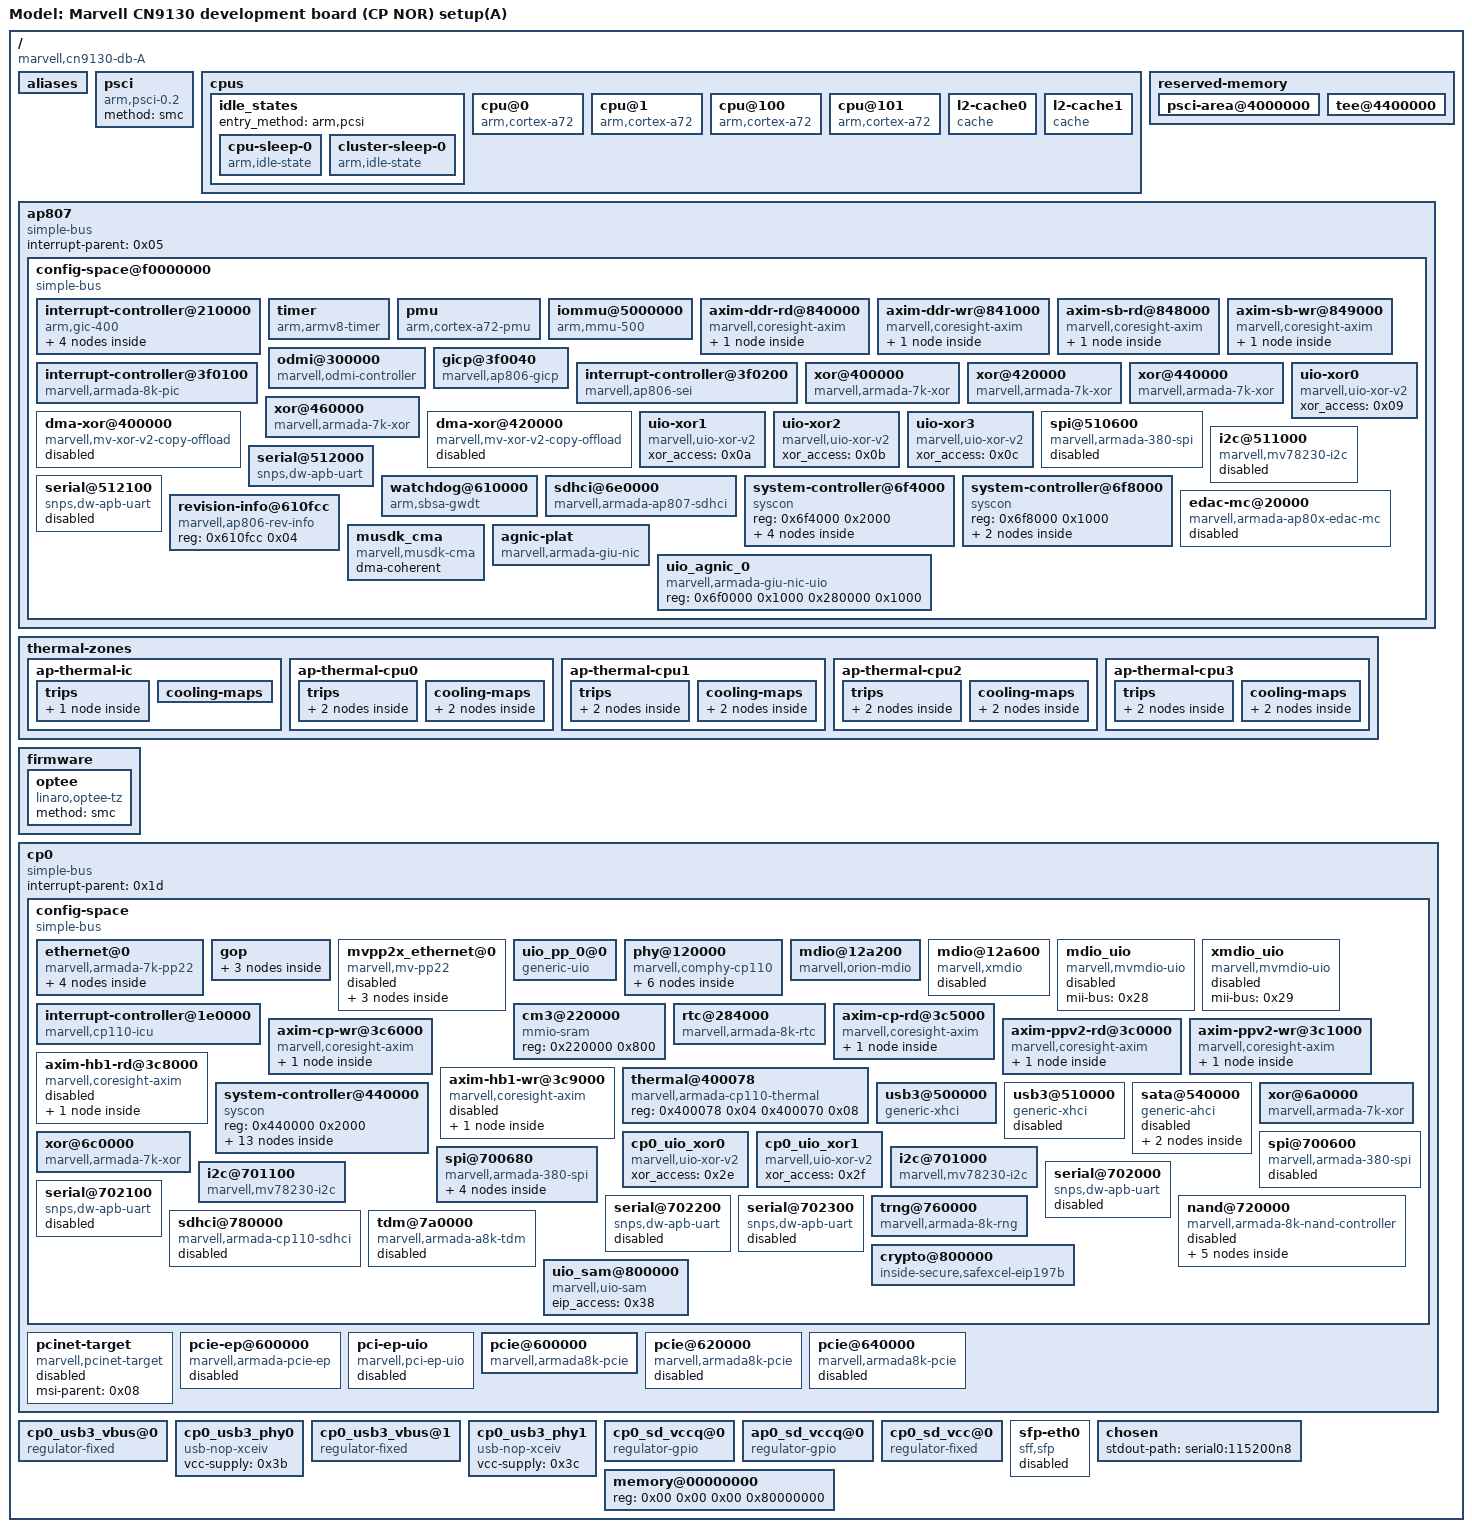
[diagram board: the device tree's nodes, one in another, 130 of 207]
/dts-v1/;

/ {
	compatible = "marvell,cn9130-db-A\0marvell,armada-ap807-quad\0marvell,armada-ap807";
	#address-cells = <0x02>;
	#size-cells = <0x02>;
	model = "Model: Marvell CN9130 development board (CP NOR) setup(A)";

	aliases {
		serial0 = "/ap807/config-space@f0000000/serial@512000";
		serial1 = "/ap807/config-space@f0000000/serial@512100";
		gpio0 = "/ap807/config-space@f0000000/system-controller@6f4000/gpio@1040";
		spi0 = "/ap807/config-space@f0000000/spi@510600";
		gpio1 = "/cp0/config-space/system-controller@440000/gpio@100";
		gpio2 = "/cp0/config-space/system-controller@440000/gpio@140";
		spi1 = "/cp0/config-space/spi@700600";
		spi2 = "/cp0/config-space/spi@700680";
		i2c0 = "/cp0/config-space/i2c@701000";
		ethernet0 = "/cp0/config-space/ethernet@0/eth0";
		ethernet1 = "/cp0/config-space/ethernet@0/eth1";
		ethernet2 = "/cp0/config-space/ethernet@0/eth2";
	};

	psci {
		compatible = "arm,psci-0.2";
		method = "smc";
	};

	cpus {
		#address-cells = <0x01>;
		#size-cells = <0x00>;

		idle_states {
			entry_method = "arm,pcsi";

			cpu-sleep-0 {
				compatible = "arm,idle-state";
				local-timer-stop;
				arm,psci-suspend-param = <0x10000>;
				entry-latency-us = <0x50>;
				exit-latency-us = <0xa0>;
				min-residency-us = <0x140>;
				linux,phandle = <0x02>;
				phandle = <0x02>;
			};

			cluster-sleep-0 {
				compatible = "arm,idle-state";
				local-timer-stop;
				arm,psci-suspend-param = <0x1010000>;
				entry-latency-us = <0x1f4>;
				exit-latency-us = <0x3e8>;
				min-residency-us = <0x9c4>;
			};
		};

		cpu@0 {
			device_type = "cpu";
			compatible = "arm,cortex-a72\0arm,armv8";
			reg = <0x00>;
			enable-method = "psci";
			#cooling-cells = <0x02>;
			clocks = <0x01 0x00>;
			cpu-idle-states = <0x02>;
			i-cache-size = <0xc000>;
			i-cache-line-size = <0x40>;
			i-cache-sets = <0x100>;
			d-cache-size = <0x8000>;
			d-cache-line-size = <0x40>;
			d-cache-sets = <0x100>;
			next-level-cache = <0x03>;
			linux,phandle = <0x12>;
			phandle = <0x12>;
		};

		cpu@1 {
			device_type = "cpu";
			compatible = "arm,cortex-a72\0arm,armv8";
			reg = <0x01>;
			enable-method = "psci";
			#cooling-cells = <0x02>;
			clocks = <0x01 0x00>;
			cpu-idle-states = <0x02>;
			i-cache-size = <0xc000>;
			i-cache-line-size = <0x40>;
			i-cache-sets = <0x100>;
			d-cache-size = <0x8000>;
			d-cache-line-size = <0x40>;
			d-cache-sets = <0x100>;
			next-level-cache = <0x03>;
			linux,phandle = <0x13>;
			phandle = <0x13>;
		};

		cpu@100 {
			device_type = "cpu";
			compatible = "arm,cortex-a72\0arm,armv8";
			reg = <0x100>;
			enable-method = "psci";
			#cooling-cells = <0x02>;
			clocks = <0x01 0x01>;
			cpu-idle-states = <0x02>;
			i-cache-size = <0xc000>;
			i-cache-line-size = <0x40>;
			i-cache-sets = <0x100>;
			d-cache-size = <0x8000>;
			d-cache-line-size = <0x40>;
			d-cache-sets = <0x100>;
			next-level-cache = <0x04>;
			linux,phandle = <0x18>;
			phandle = <0x18>;
		};

		cpu@101 {
			device_type = "cpu";
			compatible = "arm,cortex-a72\0arm,armv8";
			reg = <0x101>;
			enable-method = "psci";
			#cooling-cells = <0x02>;
			clocks = <0x01 0x01>;
			cpu-idle-states = <0x02>;
			i-cache-size = <0xc000>;
			i-cache-line-size = <0x40>;
			i-cache-sets = <0x100>;
			d-cache-size = <0x8000>;
			d-cache-line-size = <0x40>;
			d-cache-sets = <0x100>;
			next-level-cache = <0x04>;
			linux,phandle = <0x19>;
			phandle = <0x19>;
		};

		l2-cache0 {
			compatible = "cache";
			cache-size = <0x80000>;
			cache-line-size = <0x40>;
			cache-sets = <0x200>;
			linux,phandle = <0x03>;
			phandle = <0x03>;
		};

		l2-cache1 {
			compatible = "cache";
			cache-size = <0x80000>;
			cache-line-size = <0x40>;
			cache-sets = <0x200>;
			linux,phandle = <0x04>;
			phandle = <0x04>;
		};
	};

	reserved-memory {
		#address-cells = <0x02>;
		#size-cells = <0x02>;
		ranges;

		psci-area@4000000 {
			reg = <0x00 0x4000000 0x00 0x200000>;
			no-map;
		};

		tee@4400000 {
			reg = <0x00 0x4400000 0x00 0x1000000>;
			no-map;
		};
	};

	ap807 {
		#address-cells = <0x02>;
		#size-cells = <0x02>;
		compatible = "simple-bus";
		interrupt-parent = <0x05>;
		ranges;

		config-space@f0000000 {
			#address-cells = <0x01>;
			#size-cells = <0x01>;
			compatible = "simple-bus";
			ranges = <0x00 0x00 0xf0000000 0x1000000>;

			interrupt-controller@210000 {
				compatible = "arm,gic-400";
				#interrupt-cells = <0x03>;
				#address-cells = <0x01>;
				#size-cells = <0x01>;
				ranges;
				interrupt-controller;
				interrupts = <0x01 0x09 0xf04>;
				reg = <0x210000 0x10000 0x220000 0x20000 0x240000 0x20000 0x260000 0x20000>;
				linux,phandle = <0x05>;
				phandle = <0x05>;

				v2m@280000 {
					compatible = "arm,gic-v2m-frame";
					msi-controller;
					reg = <0x280000 0x1000>;
					arm,msi-base-spi = <0xa0>;
					arm,msi-num-spis = <0x20>;
					linux,phandle = <0x08>;
					phandle = <0x08>;
				};

				v2m@290000 {
					compatible = "arm,gic-v2m-frame";
					msi-controller;
					reg = <0x290000 0x1000>;
					arm,msi-base-spi = <0xc0>;
					arm,msi-num-spis = <0x20>;
				};

				v2m@2a0000 {
					compatible = "arm,gic-v2m-frame";
					msi-controller;
					reg = <0x2a0000 0x1000>;
					arm,msi-base-spi = <0xe0>;
					arm,msi-num-spis = <0x20>;
				};

				v2m@2b0000 {
					compatible = "arm,gic-v2m-frame";
					msi-controller;
					reg = <0x2b0000 0x1000>;
					arm,msi-base-spi = <0x100>;
					arm,msi-num-spis = <0x20>;
				};
			};

			timer {
				compatible = "arm,armv8-timer";
				interrupts = <0x01 0x0d 0xf08 0x01 0x0e 0xf08 0x01 0x0b 0xf08 0x01 0x0a 0xf08>;
			};

			pmu {
				compatible = "arm,cortex-a72-pmu";
				interrupt-parent = <0x06>;
				interrupts = <0x11>;
			};

			iommu@5000000 {
				compatible = "arm,mmu-500";
				reg = <0x100000 0x100000>;
				dma-coherent;
				#iommu-cells = <0x01>;
				#global-interrupts = <0x01>;
				interrupts = <0x00 0x06 0x04 0x00 0x06 0x04 0x00 0x06 0x04 0x00 0x06 0x04 0x00 0x06 0x04 0x00 0x06 0x04 0x00 0x06 0x04 0x00 0x06 0x04 0x00 0x06 0x04>;
			};

			axim-ddr-rd@840000 {
				compatible = "marvell,coresight-axim\0arm,primecell";
				reg = <0x840000 0x1000>;
				clocks = <0x07 0x03 0x07 0x05>;
				clock-names = "apb_pclk\0hclk";
				bus-width = <0x28>;

				port@0 {
				};
			};

			axim-ddr-wr@841000 {
				compatible = "marvell,coresight-axim\0arm,primecell";
				reg = <0x841000 0x1000>;
				clocks = <0x07 0x03 0x07 0x05>;
				clock-names = "apb_pclk\0hclk";
				bus-width = <0x28>;

				port@0 {
				};
			};

			axim-sb-rd@848000 {
				compatible = "marvell,coresight-axim\0arm,primecell";
				reg = <0x848000 0x1000>;
				clocks = <0x07 0x03 0x07 0x05>;
				clock-names = "apb_pclk\0hclk";
				bus-width = <0x28>;

				port@0 {
				};
			};

			axim-sb-wr@849000 {
				compatible = "marvell,coresight-axim\0arm,primecell";
				reg = <0x849000 0x1000>;
				clocks = <0x07 0x03 0x07 0x05>;
				clock-names = "apb_pclk\0hclk";
				bus-width = <0x28>;

				port@0 {
				};
			};

			odmi@300000 {
				compatible = "marvell,odmi-controller";
				interrupt-controller;
				msi-controller;
				marvell,odmi-frames = <0x04>;
				reg = <0x300000 0x4000 0x304000 0x4000 0x308000 0x4000 0x30c000 0x4000>;
				marvell,spi-base = <0x80 0x88 0x90 0x98>;
			};

			gicp@3f0040 {
				compatible = "marvell,ap806-gicp";
				reg = <0x3f0040 0x10>;
				marvell,spi-ranges = <0x40 0x40 0x120 0x40>;
				msi-controller;
				linux,phandle = <0x2a>;
				phandle = <0x2a>;
			};

			interrupt-controller@3f0100 {
				compatible = "marvell,armada-8k-pic";
				reg = <0x3f0100 0x10>;
				#interrupt-cells = <0x01>;
				interrupt-controller;
				interrupts = <0x01 0x0f 0x04>;
				linux,phandle = <0x06>;
				phandle = <0x06>;
			};

			interrupt-controller@3f0200 {
				compatible = "marvell,ap806-sei";
				reg = <0x3f0200 0x40>;
				interrupts = <0x00 0x00 0x04>;
				#interrupt-cells = <0x01>;
				interrupt-controller;
				msi-controller;
				linux,phandle = <0x0f>;
				phandle = <0x0f>;
			};

			xor@400000 {
				compatible = "marvell,armada-7k-xor\0marvell,xor-v2";
				reg = <0x400000 0x1000 0x410000 0x1000>;
				msi-parent = <0x08>;
				clocks = <0x07 0x03>;
				dma-coherent;
				linux,phandle = <0x09>;
				phandle = <0x09>;
			};

			xor@420000 {
				compatible = "marvell,armada-7k-xor\0marvell,xor-v2";
				reg = <0x420000 0x1000 0x430000 0x1000>;
				msi-parent = <0x08>;
				clocks = <0x07 0x03>;
				dma-coherent;
				linux,phandle = <0x0a>;
				phandle = <0x0a>;
			};

			xor@440000 {
				compatible = "marvell,armada-7k-xor\0marvell,xor-v2";
				reg = <0x440000 0x1000 0x450000 0x1000>;
				msi-parent = <0x08>;
				clocks = <0x07 0x03>;
				dma-coherent;
				linux,phandle = <0x0b>;
				phandle = <0x0b>;
			};

			xor@460000 {
				compatible = "marvell,armada-7k-xor\0marvell,xor-v2";
				reg = <0x460000 0x1000 0x470000 0x1000>;
				msi-parent = <0x08>;
				clocks = <0x07 0x03>;
				dma-coherent;
				linux,phandle = <0x0c>;
				phandle = <0x0c>;
			};

			dma-xor@400000 {
				compatible = "marvell,mv-xor-v2-copy-offload";
				reg = <0x400000 0x1000 0x410000 0x1000>;
				msi-parent = <0x08>;
				clocks = <0x07 0x03>;
				dma-coherent;
				status = "disabled";
			};

			dma-xor@420000 {
				compatible = "marvell,mv-xor-v2-copy-offload";
				reg = <0x420000 0x1000 0x430000 0x1000>;
				msi-parent = <0x08>;
				clocks = <0x07 0x03>;
				dma-coherent;
				status = "disabled";
			};

			uio-xor0 {
				compatible = "marvell,uio-xor-v2";
				xor_access = <0x09>;
			};

			uio-xor1 {
				compatible = "marvell,uio-xor-v2";
				xor_access = <0x0a>;
			};

			uio-xor2 {
				compatible = "marvell,uio-xor-v2";
				xor_access = <0x0b>;
			};

			uio-xor3 {
				compatible = "marvell,uio-xor-v2";
				xor_access = <0x0c>;
			};

			spi@510600 {
				compatible = "marvell,armada-380-spi";
				reg = <0x510600 0x50>;
				#address-cells = <0x01>;
				#size-cells = <0x00>;
				interrupts = <0x00 0x15 0x04>;
				clocks = <0x07 0x03>;
				status = "disabled";
			};

			i2c@511000 {
				compatible = "marvell,mv78230-i2c";
				reg = <0x511000 0x20>;
				#address-cells = <0x01>;
				#size-cells = <0x00>;
				interrupts = <0x00 0x14 0x04>;
				timeout-ms = <0x3e8>;
				clocks = <0x07 0x03>;
				status = "disabled";
			};

			serial@512000 {
				compatible = "snps,dw-apb-uart";
				reg = <0x512000 0x100>;
				reg-shift = <0x02>;
				interrupts = <0x00 0x13 0x04>;
				reg-io-width = <0x01>;
				clocks = <0x07 0x03>;
				status = "okay";
			};

			serial@512100 {
				compatible = "snps,dw-apb-uart";
				reg = <0x512100 0x100>;
				reg-shift = <0x02>;
				interrupts = <0x00 0x1d 0x04>;
				reg-io-width = <0x01>;
				clocks = <0x07 0x03>;
				status = "disabled";
			};

			watchdog@610000 {
				compatible = "arm,sbsa-gwdt";
				reg = <0x610000 0x1000 0x600000 0x1000>;
				interrupts = <0x00 0x02 0x04>;
			};

			sdhci@6e0000 {
				compatible = "marvell,armada-ap807-sdhci";
				reg = <0x6e0000 0x300>;
				interrupts = <0x00 0x10 0x04>;
				clock-names = "core";
				clocks = <0x07 0x04>;
				dma-coherent;
				status = "okay";
				pinctrl-names = "default";
				max-frequency = <0x18cba80>;
				bus-width = <0x08>;
				no-1-8-v;
				mmc-ddr-3_3v;
				disable-wp;
				broken-cd;
				cap-mmc-highspeed;
				non-removable;
				no-sdio;
				no-sd;
				vqmmc-supply = <0x325aa0>;
			};

			system-controller@6f4000 {
				compatible = "syscon\0simple-mfd";
				reg = <0x6f4000 0x2000>;

				pinctrl {
					compatible = "marvell,ap806-pinctrl";
					linux,phandle = <0x0e>;
					phandle = <0x0e>;

					uart0-pins {
						marvell,pins = "mpp11\0mpp19";
						marvell,function = "uart0";
					};
				};

				gpio@1040 {
					compatible = "marvell,armada-8k-gpio";
					offset = <0x1040>;
					ngpios = <0x14>;
					gpio-controller;
					#gpio-cells = <0x02>;
					gpio-ranges = <0x0e 0x00 0x00 0x14>;
				};

				clock {
					compatible = "marvell,ap807-clock";
					#clock-cells = <0x01>;
					linux,phandle = <0x07>;
					phandle = <0x07>;
				};
			};

			system-controller@6f8000 {
				compatible = "syscon\0simple-mfd";
				reg = <0x6f8000 0x1000>;
				#address-cells = <0x01>;
				#size-cells = <0x01>;

				thermal-sensor@80 {
					compatible = "marvell,armada-ap806-thermal";
					reg = <0x80 0x10>;
					interrupt-parent = <0x0f>;
					interrupts = <0x12>;
					#thermal-sensor-cells = <0x01>;
					linux,phandle = <0x10>;
					phandle = <0x10>;
				};

				clock-cpu {
					compatible = "marvell,ap807-cpu-clock";
					clocks = <0x07 0x00 0x07 0x01>;
					#clock-cells = <0x01>;
					linux,phandle = <0x01>;
					phandle = <0x01>;
				};
			};

			edac-mc@20000 {
				compatible = "marvell,armada-ap80x-edac-mc";
				reg = <0x20000 0x1000>;
				interrupts = <0x00 0x05 0x04>;
				status = "disabled";
			};

			revision-info@610fcc {
				compatible = "marvell,ap806-rev-info";
				reg = <0x610fcc 0x04>;
			};

			musdk_cma {
				compatible = "marvell,musdk-cma";
				dma-coherent;
			};

			agnic-plat {
				compatible = "marvell,armada-giu-nic";
				reg = <0x6f00a0 0x08>;
				msi-parent = <0x08>;
				dma-coherent;
			};

			uio_agnic_0 {
				compatible = "marvell,armada-giu-nic-uio";
				reg = <0x6f0000 0x1000 0x280000 0x1000>;
				reg-names = "agnic_regs\0msi_regs";
			};
		};
	};

	thermal-zones {

		ap-thermal-ic {
			polling-delay-passive = <0x00>;
			polling-delay = <0x00>;
			thermal-sensors = <0x10 0x00>;

			trips {

				ap-crit {
					temperature = <0x186a0>;
					hysteresis = <0x7d0>;
					type = "critical";
				};
			};

			cooling-maps {
			};
		};

		ap-thermal-cpu0 {
			polling-delay-passive = <0x3e8>;
			polling-delay = <0x3e8>;
			thermal-sensors = <0x10 0x01>;

			trips {

				cpu0-hot {
					temperature = <0x16760>;
					hysteresis = <0x7d0>;
					type = "passive";
					linux,phandle = <0x11>;
					phandle = <0x11>;
				};

				cpu0-emerg {
					temperature = <0x17ed0>;
					hysteresis = <0x7d0>;
					type = "passive";
					linux,phandle = <0x14>;
					phandle = <0x14>;
				};
			};

			cooling-maps {

				map0-hot {
					trip = <0x11>;
					cooling-device = <0x12 0x01 0x02 0x13 0x01 0x02>;
				};

				map0-ermerg {
					trip = <0x14>;
					cooling-device = <0x12 0x03 0x03 0x13 0x03 0x03>;
				};
			};
		};

		ap-thermal-cpu1 {
			polling-delay-passive = <0x3e8>;
			polling-delay = <0x3e8>;
			thermal-sensors = <0x10 0x02>;

			trips {

				cpu1-hot {
					temperature = <0x16760>;
					hysteresis = <0x7d0>;
					type = "passive";
					linux,phandle = <0x15>;
					phandle = <0x15>;
				};

				cpu1-emerg {
					temperature = <0x17ed0>;
					hysteresis = <0x7d0>;
					type = "passive";
					linux,phandle = <0x16>;
					phandle = <0x16>;
				};
			};

			cooling-maps {

				map1-hot {
					trip = <0x15>;
					cooling-device = <0x12 0x01 0x02 0x13 0x01 0x02>;
				};

				map1-emerg {
					trip = <0x16>;
					cooling-device = <0x12 0x03 0x03 0x13 0x03 0x03>;
				};
			};
		};

		ap-thermal-cpu2 {
			polling-delay-passive = <0x3e8>;
			polling-delay = <0x3e8>;
			thermal-sensors = <0x10 0x03>;

			trips {

				cpu2-hot {
					temperature = <0x16760>;
					hysteresis = <0x7d0>;
					type = "passive";
					linux,phandle = <0x17>;
					phandle = <0x17>;
				};

				cpu2-emerg {
					temperature = <0x17ed0>;
					hysteresis = <0x7d0>;
					type = "passive";
					linux,phandle = <0x1a>;
					phandle = <0x1a>;
				};
			};

			cooling-maps {

				map2-hot {
					trip = <0x17>;
					cooling-device = <0x18 0x01 0x02 0x19 0x01 0x02>;
				};

				map2-emerg {
					trip = <0x1a>;
					cooling-device = <0x18 0x03 0x03 0x19 0x03 0x03>;
				};
			};
		};

		ap-thermal-cpu3 {
			polling-delay-passive = <0x3e8>;
			polling-delay = <0x3e8>;
			thermal-sensors = <0x10 0x04>;

			trips {

				cpu3-hot {
					temperature = <0x16760>;
					hysteresis = <0x7d0>;
					type = "passive";
					linux,phandle = <0x1b>;
					phandle = <0x1b>;
				};

				cpu3-emerg {
					temperature = <0x17ed0>;
					hysteresis = <0x7d0>;
					type = "passive";
					linux,phandle = <0x1c>;
					phandle = <0x1c>;
				};
			};

			cooling-maps {

				map3-bhot {
					trip = <0x1b>;
					cooling-device = <0x18 0x01 0x02 0x19 0x01 0x02>;
				};

				map3-emerg {
					trip = <0x1c>;
					cooling-device = <0x18 0x03 0x03 0x19 0x03 0x03>;
				};
			};
		};
	};

	firmware {

		optee {
			compatible = "linaro,optee-tz";
			method = "smc";
			status = "okay";
		};
	};

	cp0 {
		#address-cells = <0x02>;
		#size-cells = <0x02>;
		compatible = "simple-bus";
		interrupt-parent = <0x1d>;
		ranges;

		config-space {
			#address-cells = <0x01>;
			#size-cells = <0x01>;
			compatible = "simple-bus";
			ranges = <0x00 0x00 0xf2000000 0x2000000>;

			ethernet@0 {
				compatible = "marvell,armada-7k-pp22";
				reg = <0x00 0x100000 0x129000 0xb000>;
				clocks = <0x1e 0x01 0x03 0x1e 0x01 0x09 0x1e 0x01 0x05 0x1e 0x01 0x06 0x1e 0x01 0x12>;
				clock-names = "pp_clk\0gop_clk\0mg_clk\0mg_core_clk\0axi_clk";
				marvell,system-controller = <0x1f>;
				status = "okay";
				dma-coherent;
				cm3-mem = <0x20>;

				eth0 {
					interrupts = <0x00 0x27 0x04 0x00 0x2b 0x04 0x00 0x2f 0x04 0x00 0x33 0x04 0x00 0x37 0x04 0x00 0x3b 0x04 0x00 0x3f 0x04 0x00 0x43 0x04 0x00 0x47 0x04 0x00 0x81 0x04>;
					interrupt-names = "hif0\0hif1\0hif2\0hif3\0hif4\0hif5\0hif6\0hif7\0hif8\0link";
					port-id = <0x00>;
					gop-port-id = <0x00>;
					status = "okay";
					phy-mode = "10gbase-kr";
					phys = <0x21 0x00>;

					fixed-link {
						speed = <0x2710>;
						full-duplex;
					};
				};

				eth1 {
					interrupts = <0x00 0x28 0x04 0x00 0x2c 0x04 0x00 0x30 0x04 0x00 0x34 0x04 0x00 0x38 0x04 0x00 0x3c 0x04 0x00 0x40 0x04 0x00 0x44 0x04 0x00 0x48 0x04 0x00 0x80 0x04>;
					interrupt-names = "hif0\0hif1\0hif2\0hif3\0hif4\0hif5\0hif6\0hif7\0hif8\0link";
					port-id = <0x01>;
					gop-port-id = <0x02>;
					status = "disabled";
					phy = <0x23>;
					phy-mode = "rgmii-id";
				};

				eth2 {
					interrupts = <0x00 0x29 0x04 0x00 0x2d 0x04 0x00 0x31 0x04 0x00 0x35 0x04 0x00 0x39 0x04 0x00 0x3d 0x04 0x00 0x41 0x04 0x00 0x45 0x04 0x00 0x49 0x04 0x00 0x7f 0x04>;
					interrupt-names = "hif0\0hif1\0hif2\0hif3\0hif4\0hif5\0hif6\0hif7\0hif8\0link";
					port-id = <0x02>;
					gop-port-id = <0x03>;
					status = "disabled";
					phy = <0x24>;
					phy-mode = "rgmii-id";
				};
			};

			gop {

				mac0 {
					interrupts = <0x00 0x81 0x04>;
					port-id = <0x00>;
					status = "disabled";
					linux,phandle = <0x25>;
					phandle = <0x25>;
				};

				mac2 {
					interrupts = <0x00 0x80 0x04>;
					port-id = <0x02>;
					status = "disabled";
					linux,phandle = <0x26>;
					phandle = <0x26>;
				};

				mac3 {
					interrupts = <0x00 0x7f 0x04>;
					port-id = <0x03>;
					status = "disabled";
					linux,phandle = <0x27>;
					phandle = <0x27>;
				};
			};

			mvpp2x_ethernet@0 {
				compatible = "marvell,mv-pp22";
				reg = <0x00 0x90000 0x129000 0x600 0x12a000 0x200 0x12a200 0x200 0x12a400 0x200 0x12a600 0x200 0x12b000 0x1000 0x130000 0x6000 0x130400 0x200 0x130600 0x200 0x130e00 0x100 0x130f00 0x100 0x441100 0x100 0x220000 0x800>;
				reg-names = "pp\0xmib\0led\0smi\0tai\0xsmi\0mg\0mspg\0xpcs\0fca\0gmac\0xlg\0rfu1\0cm3";
				clocks = <0x1e 0x01 0x03 0x1e 0x01 0x09 0x1e 0x01 0x05 0x1e 0x01 0x06 0x1e 0x01 0x12>;
				clock-names = "pp_clk\0gop_clk\0mg_clk\0mg_core_clk\0gop_core_clk";
				status = "disabled";
				dma-coherent;

				mvpp2x_eth0@010000 {
					interrupts = <0x00 0x27 0x04 0x00 0x2b 0x04 0x00 0x2f 0x04 0x00 0x33 0x04 0x00 0x37 0x04 0x00 0x3b 0x04 0x00 0x3f 0x04 0x00 0x43 0x04 0x00 0x47 0x04>;
					port-id = <0x00>;
					emac-data = <0x25>;
					status = "disabled";
				};

				mvpp2x_eth1@020000 {
					interrupts = <0x00 0x28 0x04 0x00 0x2c 0x04 0x00 0x30 0x04 0x00 0x34 0x04 0x00 0x38 0x04 0x00 0x3c 0x04 0x00 0x40 0x04 0x00 0x44 0x04 0x00 0x48 0x04>;
					port-id = <0x01>;
					emac-data = <0x26>;
					status = "disabled";
				};

				mvpp2x_eth2@030000 {
					interrupts = <0x00 0x29 0x04 0x00 0x2d 0x04 0x00 0x31 0x04 0x00 0x35 0x04 0x00 0x39 0x04 0x00 0x3d 0x04 0x00 0x41 0x04 0x00 0x45 0x04 0x00 0x49 0x04>;
					port-id = <0x02>;
					emac-data = <0x27>;
					status = "disabled";
				};
			};

			uio_pp_0@0 {
				compatible = "generic-uio";
				reg = <0x00 0x90000 0x130000 0x6000 0x220000 0x1000>;
				reg-names = "pp\0mspg\0cm3";
			};

			phy@120000 {
				compatible = "marvell,comphy-cp110";
				reg = <0x120000 0x6000>;
				reg-names = "comphy";
				marvell,system-controller = <0x1f>;
				#address-cells = <0x01>;
				#size-cells = <0x00>;

				phy@0 {
					reg = <0x00>;
					#phy-cells = <0x01>;
				};

				phy@1 {
					reg = <0x01>;
					#phy-cells = <0x01>;
				};

				phy@2 {
					reg = <0x02>;
					#phy-cells = <0x01>;
					linux,phandle = <0x21>;
					phandle = <0x21>;
				};

				phy@3 {
					reg = <0x03>;
					#phy-cells = <0x01>;
				};

				phy@4 {
					reg = <0x04>;
					#phy-cells = <0x01>;
					linux,phandle = <0x39>;
					phandle = <0x39>;
				};

				phy@5 {
					reg = <0x05>;
					#phy-cells = <0x01>;
				};
			};

			mdio@12a200 {
				#address-cells = <0x01>;
				#size-cells = <0x00>;
				compatible = "marvell,orion-mdio";
				reg = <0x12a200 0x10>;
				clocks = <0x1e 0x01 0x09 0x1e 0x01 0x05 0x1e 0x01 0x06 0x1e 0x01 0x12>;
				status = "okay";
				linux,phandle = <0x28>;
				phandle = <0x28>;
			};

			mdio@12a600 {
				#address-cells = <0x01>;
				#size-cells = <0x00>;
				compatible = "marvell,xmdio";
				reg = <0x12a600 0x10>;
				clocks = <0x1e 0x01 0x05 0x1e 0x01 0x06 0x1e 0x01 0x12>;
				status = "disabled";
				linux,phandle = <0x29>;
				phandle = <0x29>;
			};

			mdio_uio {
				compatible = "marvell,mvmdio-uio";
				mii-bus = <0x28>;
				status = "disabled";
			};

			xmdio_uio {
				compatible = "marvell,mvmdio-uio";
				mii-bus = <0x29>;
				status = "disabled";
			};

			interrupt-controller@1e0000 {
				compatible = "marvell,cp110-icu";
				reg = <0x1e0000 0x440>;
				#interrupt-cells = <0x03>;
				interrupt-controller;
				msi-parent = <0x2a>;
				linux,phandle = <0x1d>;
				phandle = <0x1d>;
			};

			cm3@220000 {
				compatible = "mmio-sram";
				reg = <0x220000 0x800>;
				#address-cells = <0x01>;
				#size-cells = <0x01>;
				ranges = <0x00 0x220000 0x800>;
				linux,phandle = <0x20>;
				phandle = <0x20>;
			};

			rtc@284000 {
				compatible = "marvell,armada-8k-rtc";
				reg = <0x284000 0x20 0x284080 0x24>;
				reg-names = "rtc\0rtc-soc";
				interrupts = <0x00 0x4d 0x04>;
			};

			axim-cp-rd@3c5000 {
				compatible = "marvell,coresight-axim\0arm,primecell";
				reg = <0x3c5000 0x1000>;
				clocks = <0x1e 0x01 0x03>;
				clock-names = "apb_pclk";
				bus-width = <0x28>;

				port@0 {
				};
			};

			axim-cp-wr@3c6000 {
				compatible = "marvell,coresight-axim\0arm,primecell";
				reg = <0x3c6000 0x1000>;
				clocks = <0x1e 0x01 0x03>;
				clock-names = "apb_pclk";
				bus-width = <0x28>;

				port@0 {
				};
			};

			axim-ppv2-rd@3c0000 {
				compatible = "marvell,coresight-axim\0arm,primecell";
				reg = <0x3c0000 0x1000>;
				clocks = <0x1e 0x01 0x03>;
				clock-names = "apb_pclk";
				bus-width = <0x28>;

				port@0 {
				};
			};

			axim-ppv2-wr@3c1000 {
				compatible = "marvell,coresight-axim\0arm,primecell";
				reg = <0x3c1000 0x1000>;
				clocks = <0x1e 0x01 0x03>;
				clock-names = "apb_pclk";
				bus-width = <0x28>;

				port@0 {
				};
			};

			axim-hb1-rd@3c8000 {
				compatible = "marvell,coresight-axim\0arm,primecell";
				reg = <0x3c8000 0x1000>;
				clocks = <0x1e 0x01 0x03>;
				clock-names = "apb_pclk";
				bus-width = <0x28>;
				status = "disabled";

				port@0 {
				};
			};

			axim-hb1-wr@3c9000 {
				compatible = "marvell,coresight-axim\0arm,primecell";
				reg = <0x3c9000 0x1000>;
				clocks = <0x1e 0x01 0x03>;
				clock-names = "apb_pclk";
				bus-width = <0x28>;
				status = "disabled";

				port@0 {
				};
			};

			thermal@400078 {
				compatible = "marvell,armada-cp110-thermal";
				reg = <0x400078 0x04 0x400070 0x08>;
			};

			system-controller@440000 {
				compatible = "syscon\0simple-mfd";
				reg = <0x440000 0x2000>;
				linux,phandle = <0x1f>;
				phandle = <0x1f>;

				clock {
					compatible = "marvell,cp110-clock";
					#clock-cells = <0x02>;
					linux,phandle = <0x1e>;
					phandle = <0x1e>;
				};

				gpio@100 {
					compatible = "marvell,armada-8k-gpio";
					offset = <0x100>;
					ngpios = <0x20>;
					gpio-controller;
					#gpio-cells = <0x02>;
					gpio-ranges = <0x2b 0x00 0x00 0x20>;
					interrupt-controller;
					interrupts = <0x00 0x56 0x04 0x00 0x55 0x04 0x00 0x54 0x04 0x00 0x53 0x04>;
					status = "okay";
				};

				gpio@140 {
					compatible = "marvell,armada-8k-gpio";
					offset = <0x140>;
					ngpios = <0x1f>;
					gpio-controller;
					#gpio-cells = <0x02>;
					gpio-ranges = <0x2b 0x00 0x20 0x1f>;
					interrupt-controller;
					interrupts = <0x00 0x52 0x04 0x00 0x51 0x04 0x00 0x50 0x04 0x00 0x4f 0x04>;
					status = "okay";
					linux,phandle = <0x35>;
					phandle = <0x35>;
				};

				pinctrl {
					compatible = "marvell,cp115-standalone-pinctrl";
					linux,phandle = <0x2b>;
					phandle = <0x2b>;

					cp0-i2c-pins-0 {
						marvell,pins = "mpp37\0mpp38";
						marvell,function = "i2c0";
						linux,phandle = <0x31>;
						phandle = <0x31>;
					};

					cp0-i2c-pins-1 {
						marvell,pins = "mpp35\0mpp36";
						marvell,function = "i2c1";
					};

					cp0-ge-rgmii-pins-0 {
						marvell,pins = "mpp0\0mpp1\0mpp2\0mpp3\0mpp4\0mpp5\0mpp6\0mpp7\0mpp8\0mpp9\0mpp10\0mpp11";
						marvell,function = "ge0";
					};

					cp0-ge-rgmii-pins-1 {
						marvell,pins = "mpp44\0mpp45\0mpp46\0mpp47\0mpp48\0mpp49\0mpp50\0mpp51\0mpp52\0mpp53\0mpp54\0mpp55";
						marvell,function = "ge1";
					};

					cp0-sdhci-cd-pins-0 {
						marvell,pins = "mpp43";
						marvell,function = "gpio";
						linux,phandle = <0x34>;
						phandle = <0x34>;
					};

					cp0-sdhi-pins-0 {
						marvell,pins = "mpp56\0mpp57\0mpp58\0mpp59\0mpp60\0mpp61";
						marvell,function = "sdio";
						linux,phandle = <0x33>;
						phandle = <0x33>;
					};

					cp0-spi-pins-0 {
						marvell,pins = "mpp13\0mpp14\0mpp15\0mpp16";
						marvell,function = "spi1";
						linux,phandle = <0x30>;
						phandle = <0x30>;
					};

					nand-pins {
						marvell,pins = "mpp15\0mpp16\0mpp17\0mpp18\0mpp19\0mpp20\0mpp21\0mpp22\0mpp23\0mpp24\0mpp25\0mpp26\0mpp27";
						marvell,function = "dev";
						linux,phandle = <0x32>;
						phandle = <0x32>;
					};

					nand-rb {
						marvell,pins = "mpp13";
						marvell,function = "nf";
					};
				};
			};

			usb3@500000 {
				compatible = "generic-xhci";
				reg = <0x500000 0x4000>;
				dma-coherent;
				interrupts = <0x00 0x6a 0x04>;
				clock-names = "core\0reg";
				clocks = <0x1e 0x01 0x16 0x1e 0x01 0x10>;
				status = "okay";
			};

			usb3@510000 {
				compatible = "generic-xhci";
				reg = <0x510000 0x4000>;
				dma-coherent;
				interrupts = <0x00 0x69 0x04>;
				clock-names = "core\0reg";
				clocks = <0x1e 0x01 0x17 0x1e 0x01 0x10>;
				status = "disabled";
			};

			sata@540000 {
				compatible = "generic-ahci";
				reg = <0x540000 0x30000>;
				dma-coherent;
				interrupts = <0x00 0x6b 0x04>;
				clocks = <0x1e 0x01 0x0f 0x1e 0x01 0x10>;
				status = "disabled";
				#address-cells = <0x01>;
				#size-cells = <0x00>;

				sata-port@0 {
					reg = <0x00>;
					satus = "disabled";
				};

				sata-port@1 {
					reg = <0x01>;
					status = "disabled";
				};
			};

			xor@6a0000 {
				compatible = "marvell,armada-7k-xor\0marvell,xor-v2";
				reg = <0x6a0000 0x1000 0x6b0000 0x1000>;
				dma-coherent;
				msi-parent = <0x08>;
				clock-names = "core\0reg";
				clocks = <0x1e 0x01 0x08 0x1e 0x01 0x0e>;
				linux,phandle = <0x2e>;
				phandle = <0x2e>;
			};

			xor@6c0000 {
				compatible = "marvell,armada-7k-xor\0marvell,xor-v2";
				reg = <0x6c0000 0x1000 0x6d0000 0x1000>;
				dma-coherent;
				msi-parent = <0x08>;
				clock-names = "core\0reg";
				clocks = <0x1e 0x01 0x07 0x1e 0x01 0x0e>;
				linux,phandle = <0x2f>;
				phandle = <0x2f>;
			};

			cp0_uio_xor0 {
				compatible = "marvell,uio-xor-v2";
				xor_access = <0x2e>;
			};

			cp0_uio_xor1 {
				compatible = "marvell,uio-xor-v2";
				xor_access = <0x2f>;
			};

			spi@700600 {
				compatible = "marvell,armada-380-spi";
				reg = <0x700600 0x50>;
				#address-cells = <0x01>;
				#size-cells = <0x00>;
				cell-index = <0x01>;
				clock-names = "core\0axi";
				clocks = <0x1e 0x01 0x15 0x1e 0x01 0x11>;
				status = "disabled";
			};

			spi@700680 {
				compatible = "marvell,armada-380-spi";
				reg = <0x700680 0x50 0x2000000 0x1000000>;
				#address-cells = <0x01>;
				#size-cells = <0x00>;
				cell-index = <0x02>;
				clock-names = "core\0axi";
				clocks = <0x1e 0x01 0x15 0x1e 0x01 0x11>;
				status = "okay";
				pinctrl-names = "default";
				pinctrl-0 = <0x30>;

				spi-flash@0 {
					#address-cells = <0x01>;
					#size-cells = <0x01>;
					compatible = "jedec,spi-nor";
					reg = <0x00>;
					spi-max-frequency = <0x2625a00>;

					partitions {
						compatible = "fixed-partitions";
						#address-cells = <0x01>;
						#size-cells = <0x01>;

						partition@0 {
							label = "U-Boot";
							reg = <0x00 0x200000>;
						};

						partition@400000 {
							label = "Filesystem";
							reg = <0x200000 0xe00000>;
						};
					};
				};
			};

			i2c@701000 {
				compatible = "marvell,mv78230-i2c";
				reg = <0x701000 0x20>;
				#address-cells = <0x01>;
				#size-cells = <0x00>;
				interrupts = <0x00 0x78 0x04>;
				clock-names = "core\0reg\0axi";
				clocks = <0x1e 0x01 0x15 0x1e 0x01 0x11 0x1e 0x01 0x12>;
				status = "okay";
				clock-frequency = <0x186a0>;
				pinctrl-names = "default";
				pinctrl-0 = <0x31>;
			};

			i2c@701100 {
				compatible = "marvell,mv78230-i2c";
				reg = <0x701100 0x20>;
				#address-cells = <0x01>;
				#size-cells = <0x00>;
				interrupts = <0x00 0x79 0x04>;
				clock-names = "core\0reg\0axi";
				clocks = <0x1e 0x01 0x15 0x1e 0x01 0x11 0x1e 0x01 0x12>;
				status = "okay";
				clock-frequency = <0x186a0>;
			};

			serial@702000 {
				compatible = "snps,dw-apb-uart";
				reg = <0x702000 0x100>;
				reg-shift = <0x02>;
				interrupts = <0x00 0x7a 0x04>;
				reg-io-width = <0x01>;
				clock-names = "baudclk\0apb_pclk";
				clocks = <0x1e 0x01 0x15 0x1e 0x01 0x11>;
				status = "disabled";
			};

			serial@702100 {
				compatible = "snps,dw-apb-uart";
				reg = <0x702100 0x100>;
				reg-shift = <0x02>;
				interrupts = <0x00 0x7b 0x04>;
				reg-io-width = <0x01>;
				clock-names = "baudclk\0apb_pclk";
				clocks = <0x1e 0x01 0x15 0x1e 0x01 0x11>;
				status = "disabled";
			};

			serial@702200 {
				compatible = "snps,dw-apb-uart";
				reg = <0x702200 0x100>;
				reg-shift = <0x02>;
				interrupts = <0x00 0x7c 0x04>;
				reg-io-width = <0x01>;
				clock-names = "baudclk\0apb_pclk";
				clocks = <0x1e 0x01 0x15 0x1e 0x01 0x11>;
				status = "disabled";
			};

			serial@702300 {
				compatible = "snps,dw-apb-uart";
				reg = <0x702300 0x100>;
				reg-shift = <0x02>;
				interrupts = <0x00 0x7d 0x04>;
				reg-io-width = <0x01>;
				clock-names = "baudclk\0apb_pclk";
				clocks = <0x1e 0x01 0x15 0x1e 0x01 0x11>;
				status = "disabled";
			};

			nand@720000 {
				compatible = "marvell,armada-8k-nand-controller\0marvell,armada370-nand-controller";
				reg = <0x720000 0x54>;
				#address-cells = <0x01>;
				#size-cells = <0x00>;
				interrupts = <0x00 0x73 0x04>;
				clock-names = "core\0reg";
				clocks = <0x1e 0x01 0x02 0x1e 0x01 0x11>;
				marvell,system-controller = <0x1f>;
				status = "disabled";
				pinctrl-names = "default";
				pinctrl-0 = <0x32>;

				nand@0 {
					reg = <0x00>;
					label = "main-storage";
					nand-rb = <0x00>;
					nand-ecc-mode = "hw";
					nand-on-flash-bbt;
					nand-ecc-strength = <0x08>;
					nand-ecc-step-size = <0x200>;

					partitions {
						compatible = "fixed-partitions";
						#address-cells = <0x01>;
						#size-cells = <0x01>;

						partition@0 {
							label = "U-Boot";
							reg = <0x00 0x200000>;
						};

						partition@200000 {
							label = "Linux";
							reg = <0x200000 0xe00000>;
						};

						partition@1000000 {
							label = "Filesystem";
							reg = <0x1000000 0x3f000000>;
						};
					};
				};
			};

			trng@760000 {
				compatible = "marvell,armada-8k-rng\0inside-secure,safexcel-eip76";
				reg = <0x760000 0x7d>;
				interrupts = <0x00 0x5f 0x04>;
				clock-names = "core\0reg";
				clocks = <0x1e 0x01 0x19 0x1e 0x01 0x11>;
				status = "okay";
			};

			sdhci@780000 {
				compatible = "marvell,armada-cp110-sdhci";
				reg = <0x780000 0x300>;
				interrupts = <0x00 0x1b 0x04>;
				clock-names = "core\0axi";
				clocks = <0x1e 0x01 0x04 0x1e 0x01 0x12>;
				dma-coherent;
				status = "disabled";
			};

			tdm@7a0000 {
				compatible = "marvell,armada-a8k-tdm";
				reg = <0x7a0000 0x20000>;
				reg-names = "tdm_regs";
				interrupts = <0x00 0x6f 0x04 0x00 0x70 0x04 0x00 0x71 0x04>;
				cell-index = <0x00>;
				clock-names = "core\0axi";
				clocks = <0x1e 0x01 0x01 0x1e 0x01 0x11>;
				status = "disabled";
			};

			crypto@800000 {
				compatible = "inside-secure,safexcel-eip197b";
				reg = <0x800000 0x200000>;
				interrupts = <0x00 0x57 0x04 0x00 0x58 0x04 0x00 0x59 0x04 0x00 0x5a 0x04 0x00 0x5b 0x04 0x00 0x5c 0x04>;
				interrupt-names = "mem\0ring0\0ring1\0ring2\0ring3\0eip";
				clock-names = "core\0reg";
				clocks = <0x1e 0x01 0x1a 0x1e 0x01 0x11>;
				cell-index = <0x00>;
				dma-coherent;
				status = "okay";
				linux,phandle = <0x38>;
				phandle = <0x38>;
			};

			uio_sam@800000 {
				compatible = "marvell,uio-sam";
				eip_access = <0x38>;
			};
		};

		pcinet-target {
			compatible = "marvell,pcinet-target";
			msi-parent = <0x08>;
			status = "disabled";
		};

		pcie-ep@600000 {
			compatible = "marvell,armada-pcie-ep\0snps,dw-pcie";
			reg = <0x00 0xf2600000 0x00 0x4000 0x00 0xf2608000 0x00 0x80000 0x00 0xf2604000 0x00 0x1000>;
			reg-names = "core\0lm\0shadow_core";
			clocks = <0x1e 0x01 0x0d>;
			status = "disabled";
		};

		pci-ep-uio {
			compatible = "marvell,pci-ep-uio";
			reg = <0x00 0x00 0x00 0x100000 0x00 0x3f000000 0x00 0x1000000 0x00 0xf0000000 0x00 0x1000000 0x80 0x00 0x08 0x00>;
			reg-names = "bar0\0bar2\0bar4\0host-map";
			status = "disabled";
		};

		pcie@600000 {
			compatible = "marvell,armada8k-pcie\0snps,dw-pcie";
			reg = <0x00 0xf2600000 0x00 0x10000 0x00 0xdff00000 0x00 0x80000>;
			reg-names = "ctrl\0config";
			#address-cells = <0x03>;
			#size-cells = <0x02>;
			#interrupt-cells = <0x01>;
			device_type = "pci";
			dma-coherent;
			msi-parent = <0x08>;
			bus-range = <0x00 0xff>;
			ranges = <0x82000000 0x00 0xc0000000 0x00 0xc0000000 0x00 0x1ff00000>;
			interrupt-map-mask = <0x00 0x00 0x00 0x00>;
			interrupt-map = <0x00 0x00 0x00 0x00 0x1d 0x00 0x16 0x04>;
			interrupts = <0x00 0x16 0x04>;
			num-lanes = <0x01>;
			clock-names = "core\0reg";
			clocks = <0x1e 0x01 0x0d 0x1e 0x01 0x0e>;
			status = "okay";
			num-viewport = <0x08>;
			phys = <0x39 0x00>;
		};

		pcie@620000 {
			compatible = "marvell,armada8k-pcie\0snps,dw-pcie";
			reg = <0x00 0xf2620000 0x00 0x10000 0x00 0xe0f00000 0x00 0x80000>;
			reg-names = "ctrl\0config";
			#address-cells = <0x03>;
			#size-cells = <0x02>;
			#interrupt-cells = <0x01>;
			device_type = "pci";
			dma-coherent;
			msi-parent = <0x08>;
			bus-range = <0x00 0xff>;
			ranges = <0x82000000 0x00 0xe0000000 0x00 0xe0000000 0x00 0xf00000>;
			interrupt-map-mask = <0x00 0x00 0x00 0x00>;
			interrupt-map = <0x00 0x00 0x00 0x00 0x1d 0x00 0x18 0x04>;
			interrupts = <0x00 0x18 0x04>;
			num-lanes = <0x01>;
			clock-names = "core\0reg";
			clocks = <0x1e 0x01 0x0b 0x1e 0x01 0x0e>;
			status = "disabled";
		};

		pcie@640000 {
			compatible = "marvell,armada8k-pcie\0snps,dw-pcie";
			reg = <0x00 0xf2640000 0x00 0x10000 0x00 0xe1f00000 0x00 0x80000>;
			reg-names = "ctrl\0config";
			#address-cells = <0x03>;
			#size-cells = <0x02>;
			#interrupt-cells = <0x01>;
			device_type = "pci";
			dma-coherent;
			msi-parent = <0x08>;
			bus-range = <0x00 0xff>;
			ranges = <0x82000000 0x00 0xe1000000 0x00 0xe1000000 0x00 0xf00000>;
			interrupt-map-mask = <0x00 0x00 0x00 0x00>;
			interrupt-map = <0x00 0x00 0x00 0x00 0x1d 0x00 0x17 0x04>;
			interrupts = <0x00 0x17 0x04>;
			num-lanes = <0x01>;
			clock-names = "core\0reg";
			clocks = <0x1e 0x01 0x0c 0x1e 0x01 0x0e>;
			status = "disabled";
		};
	};

	cp0_usb3_vbus@0 {
		compatible = "regulator-fixed";
		regulator-name = "cp0-xhci0-vbus";
		regulator-min-microvolt = <0x4c4b40>;
		regulator-max-microvolt = <0x4c4b40>;
		enable-active-high;
		gpio = <0x3a 0x00 0x00>;
		linux,phandle = <0x3b>;
		phandle = <0x3b>;
	};

	cp0_usb3_phy0 {
		compatible = "usb-nop-xceiv";
		vcc-supply = <0x3b>;
	};

	cp0_usb3_vbus@1 {
		compatible = "regulator-fixed";
		regulator-name = "cp0-xhci1-vbus";
		regulator-min-microvolt = <0x4c4b40>;
		regulator-max-microvolt = <0x4c4b40>;
		enable-active-high;
		gpio = <0x3a 0x01 0x00>;
		linux,phandle = <0x3c>;
		phandle = <0x3c>;
	};

	cp0_usb3_phy1 {
		compatible = "usb-nop-xceiv";
		vcc-supply = <0x3c>;
	};

	cp0_sd_vccq@0 {
		compatible = "regulator-gpio";
		regulator-name = "cp0_sd_vccq";
		regulator-min-microvolt = <0x1b7740>;
		regulator-max-microvolt = <0x325aa0>;
		gpios = <0x3a 0x0f 0x00>;
		states = <0x1b7740 0x01 0x325aa0 0x00>;
		linux,phandle = <0x36>;
		phandle = <0x36>;
	};

	ap0_sd_vccq@0 {
		compatible = "regulator-gpio";
		regulator-name = "ap0_sd_vccq";
		regulator-min-microvolt = <0x1b7740>;
		regulator-max-microvolt = <0x325aa0>;
		gpios = <0x3a 0x08 0x00>;
		states = <0x1b7740 0x01 0x325aa0 0x00>;
		linux,phandle = <0x0d>;
		phandle = <0x0d>;
	};

	cp0_sd_vcc@0 {
		compatible = "regulator-fixed";
		regulator-name = "cp0_sd_vcc";
		regulator-min-microvolt = <0x325aa0>;
		regulator-max-microvolt = <0x325aa0>;
		gpio = <0x3a 0x0e 0x00>;
		enable-active-high;
		regulator-always-on;
		linux,phandle = <0x37>;
		phandle = <0x37>;
	};

	sfp-eth0 {
		compatible = "sff,sfp";
		i2c-bus = <0x3d>;
		los-gpio = <0x3e 0x0b 0x00>;
		mod-def0-gpio = <0x3e 0x0a 0x01>;
		tx-disable-gpio = <0x3e 0x09 0x00>;
		tx-fault-gpio = <0x3e 0x08 0x00>;
		status = "disabled";
		linux,phandle = <0x22>;
		phandle = <0x22>;
	};

	chosen {
		stdout-path = "serial0:115200n8";
	};

	memory@00000000 {
		device_type = "memory";
		reg = <0x00 0x00 0x00 0x80000000>;
	};
};
